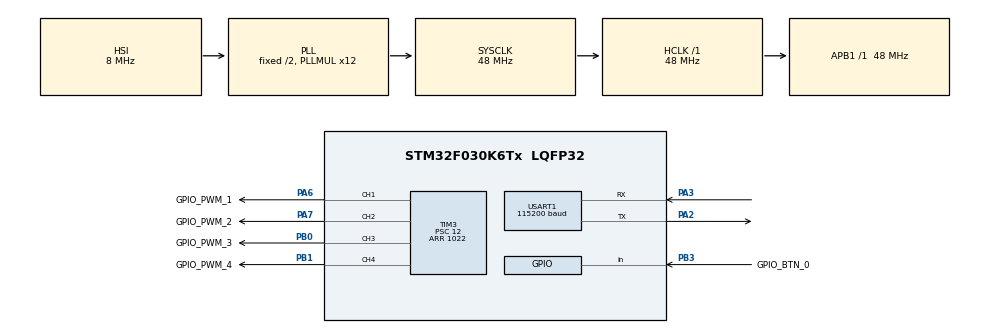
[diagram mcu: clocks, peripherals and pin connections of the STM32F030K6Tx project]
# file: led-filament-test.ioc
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Mcu.Family=STM32F0
Mcu.Name=STM32F030K6Tx
Mcu.Package=LQFP32
NVIC.USART1_IRQn=true\:0\:0\:false\:false\:false\:true\:true\:true
PA13.Mode=Serial_Wire
PA13.Signal=SYS_SWDIO
PA14.Mode=Serial_Wire
PA14.Signal=SYS_SWCLK
PA2.Mode=Asynchronous
PA2.Signal=USART1_TX
PA3.Mode=Asynchronous
PA3.Signal=USART1_RX
PA6.GPIO_Label=GPIO_PWM_1
PA6.GPIO_Speed=GPIO_SPEED_FREQ_HIGH
PA6.Signal=S_TIM3_CH1
PA7.GPIO_Label=GPIO_PWM_2
PA7.GPIO_Speed=GPIO_SPEED_FREQ_HIGH
PA7.Signal=S_TIM3_CH2
PB0.GPIO_Label=GPIO_PWM_3
PB0.GPIO_Speed=GPIO_SPEED_FREQ_HIGH
PB0.Signal=S_TIM3_CH3
PB1.GPIO_Label=GPIO_PWM_4
PB1.GPIO_Speed=GPIO_SPEED_FREQ_HIGH
PB1.Signal=S_TIM3_CH4
PB3.GPIO_Label=GPIO_BTN_0
PB3.Signal=GPIO_Input
ProjectManager.HeapSize=0x200
ProjectManager.StackSize=0x400
ProjectManager.TargetToolchain=STM32CubeIDE
RCC.AHBFreq_Value=48000000
RCC.APB1Freq_Value=48000000
RCC.APB1TimFreq_Value=48000000
RCC.HCLKFreq_Value=48000000
RCC.PLLMUL=RCC_PLL_MUL12
RCC.SYSCLKFreq_VALUE=48000000
RCC.SYSCLKSource=RCC_SYSCLKSOURCE_PLLCLK
SH.S_TIM3_CH1.0=TIM3_CH1,PWM Generation1 CH1
SH.S_TIM3_CH2.0=TIM3_CH2,PWM Generation2 CH2
SH.S_TIM3_CH3.0=TIM3_CH3,PWM Generation3 CH3
SH.S_TIM3_CH4.0=TIM3_CH4,PWM Generation4 CH4
TIM3.Channel-PWM\ Generation1\ CH1=TIM_CHANNEL_1
TIM3.Channel-PWM\ Generation2\ CH2=TIM_CHANNEL_2
TIM3.Channel-PWM\ Generation3\ CH3=TIM_CHANNEL_3
TIM3.Channel-PWM\ Generation4\ CH4=TIM_CHANNEL_4
TIM3.Period=1022
TIM3.Prescaler=12
USART1.BaudRate=115200
USART1.VirtualMode-Asynchronous=VM_ASYNC
VP_TIM3_VS_ClockSourceINT.Mode=Internal
board=custom

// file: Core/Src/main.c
/* USER CODE BEGIN Header */
/**
  ******************************************************************************
  * @file           : main.c
  * @brief          : Main program body
  ******************************************************************************
  * @attention
  *
  * Copyright (c) 2022 STMicroelectronics.
  * All rights reserved.
  *
  * This software is licensed under terms that can be found in the LICENSE file
  * in the root directory of this software component.
  * If no LICENSE file comes with this software, it is provided AS-IS.
  *
  ******************************************************************************
  */
/* USER CODE END Header */
#include "main.h"
#include "tim.h"
#include "usart.h"
#include "gpio.h"

/* USER CODE BEGIN Includes */
#include "application/appmain.h"
#include "middleware/pwmled.h"
#include "middleware/uart.h"
/* USER CODE END Includes */

void SystemClock_Config(void);

int main(void)
{

  /* MCU Configuration--------------------------------------------------------*/

  /* Reset of all peripherals, Initializes the Flash interface and the Systick. */
  HAL_Init();

  /* Configure the system clock */
  SystemClock_Config();

  /* Initialize all configured peripherals */
  MX_GPIO_Init();
  MX_TIM3_Init();
  MX_USART1_UART_Init();
  /* USER CODE BEGIN 2 */
  UART_init();
  PWMLED_init();
  /* USER CODE END 2 */

  /* Infinite loop */
  while (1)
  {

    /* USER CODE BEGIN 3 */
      APP_task();
  }
  /* USER CODE END 3 */
}

void SystemClock_Config(void)
{
  RCC_OscInitTypeDef RCC_OscInitStruct = {0};
  RCC_ClkInitTypeDef RCC_ClkInitStruct = {0};
  RCC_PeriphCLKInitTypeDef PeriphClkInit = {0};

  /** Initializes the RCC Oscillators according to the specified parameters
  * in the RCC_OscInitTypeDef structure.
  */
  RCC_OscInitStruct.OscillatorType = RCC_OSCILLATORTYPE_HSI;
  RCC_OscInitStruct.HSIState = RCC_HSI_ON;
  RCC_OscInitStruct.HSICalibrationValue = RCC_HSICALIBRATION_DEFAULT;
  RCC_OscInitStruct.PLL.PLLState = RCC_PLL_ON;
  RCC_OscInitStruct.PLL.PLLSource = RCC_PLLSOURCE_HSI;
  RCC_OscInitStruct.PLL.PLLMUL = RCC_PLL_MUL12;
  RCC_OscInitStruct.PLL.PREDIV = RCC_PREDIV_DIV1;
  if (HAL_RCC_OscConfig(&RCC_OscInitStruct) != HAL_OK)
  {
    Error_Handler();
  }

  /** Initializes the CPU, AHB and APB buses clocks
  */
  RCC_ClkInitStruct.ClockType = RCC_CLOCKTYPE_HCLK|RCC_CLOCKTYPE_SYSCLK
                              |RCC_CLOCKTYPE_PCLK1;
  RCC_ClkInitStruct.SYSCLKSource = RCC_SYSCLKSOURCE_PLLCLK;
  RCC_ClkInitStruct.AHBCLKDivider = RCC_SYSCLK_DIV1;
  RCC_ClkInitStruct.APB1CLKDivider = RCC_HCLK_DIV1;

  if (HAL_RCC_ClockConfig(&RCC_ClkInitStruct, FLASH_LATENCY_1) != HAL_OK)
  {
    Error_Handler();
  }
  PeriphClkInit.PeriphClockSelection = RCC_PERIPHCLK_USART1;
  PeriphClkInit.Usart1ClockSelection = RCC_USART1CLKSOURCE_PCLK1;
  if (HAL_RCCEx_PeriphCLKConfig(&PeriphClkInit) != HAL_OK)
  {
    Error_Handler();
  }
}

/* USER CODE BEGIN 4 */

void SysTick_Handler(void)
{
    static int ps = 0; // pre scaler to create 10ms tmr_x decrement

    HAL_IncTick();

    ++ps;

    if (ps == 10)
    {
        ps = 0;
        APP_timehandler_10ms();
    }
}

/* USER CODE END 4 */

void Error_Handler(void)
{
  __disable_irq();
  while (1)
  {
  }
}
